VERSION "1.0"

NS_ :

BS_:
BU_: ECU_Engine ECU_Transmission Gateway Dashboard
VAL_TABLE_ EngineState 0 "Off" 1 "Cranking" 2 "Running" 3 "Error" ;
VAL_TABLE_ GearPosition 0 "Park" 1 "Reverse" 2 "Neutral" 3 "Drive" 4 "Sport" 5 "Manual" ;
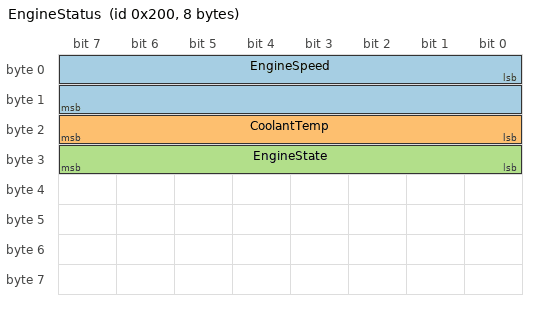
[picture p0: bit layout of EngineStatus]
BO_ 512 EngineStatus: 8 ECU_Engine
 SG_ EngineSpeed : 0|16@1+ (0.25,0.0) [0.0|16383.75] "rpm" Gateway,Dashboard
 SG_ CoolantTemp : 16|8@1+ (1.0,-40.0) [-40.0|215.0] "°C" Gateway,Dashboard
 SG_ EngineState : 24|8@1+ (1.0,0.0) [0.0|3.0] "" Gateway

BO_ 528 VehicleSpeed: 8 ECU_Engine
 SG_ VehicleSpeed : 0|16@1+ (0.01,0.0) [0.0|655.35] "km/h" Dashboard,Gateway

BO_ 544 TransmissionStatus: 8 ECU_Transmission
 SG_ CurrentGear : 0|8@1+ (1.0,0.0) [0.0|5.0] "" Dashboard,Gateway
 SG_ TransmissionTemp : 8|8@1+ (1.0,-40.0) [-40.0|215.0] "°C" Gateway

CM_ BU_ ECU_Engine "Engine Control Unit";
CM_ BU_ ECU_Transmission "Transmission Control Unit";
CM_ BU_ Gateway "Central Gateway";
CM_ BU_ Dashboard "Instrument Cluster";
CM_ BO_ 512 "Engine status and temperature";
CM_ BO_ 528 "Vehicle speed information";
CM_ BO_ 544 "Transmission status and gear position";
CM_ SG_ 512 EngineSpeed "Engine rotational speed";
CM_ SG_ 512 CoolantTemp "Engine coolant temperature";
CM_ SG_ 512 EngineState "Current engine state";
CM_ SG_ 528 VehicleSpeed "Vehicle speed from wheel sensors";
CM_ SG_ 544 CurrentGear "Current gear position";
CM_ SG_ 544 TransmissionTemp "Transmission fluid temperature";
BA_DEF_ "BusType" STRING ;
BA_DEF_ BO_ "GenMsgCycleTime" INT 0 10000;
BA_DEF_ BO_ "GenMsgSendType" STRING ;
BA_DEF_DEF_ "BusType" "CAN";
BA_DEF_DEF_ "GenMsgCycleTime" 0;
BA_DEF_DEF_ "GenMsgSendType" "Cyclic";
BA_ "GenMsgCycleTime" BO_ 512 10;
BA_ "GenMsgCycleTime" BO_ 528 20;
BA_ "GenMsgCycleTime" BO_ 544 50;
VAL_ 512 EngineState 0 "Off" 1 "Cranking" 2 "Running" 3 "Error" ;
VAL_ 544 CurrentGear 0 "Park" 1 "Reverse" 2 "Neutral" 3 "Drive" 4 "Sport" 5 "Manual" ;
